VERSION ""

NS_ :

BS_:

BU_: Gateway BMS MCU VCU
VAL_TABLE_ vtbSensorReqCause 15 "SNA" 2 "by Request 2" 1 "by Request 1" 0 "normal cycle" ;
VAL_TABLE_ vtbErrorDescription 255 "ERROR" ;

BO_ 771 m_BMS_DiagRes: 2 BMS
 SG_ s_BMS_SoT_DiagRes : 8|8@1+ (1,0) [0|255] ""  Gateway
 SG_ s_BMS_SoC_DiagRes : 0|8@1+ (1,0) [0|255] ""  Gateway

BO_ 770 m_VCU_DiagRes: 2 VCU
 SG_ s_VCU_Accel_DiagRes : 0|8@1+ (1,0) [0|255] ""  Gateway
 SG_ s_VCU_Transmisson_DiagRes : 8|8@1+ (1,0) [0|255] ""  Gateway

BO_ 769 m_BMS_DiagReq: 1 Gateway
 SG_ s_BMS_DiagReq : 0|1@1+ (1,0) [0|1] ""  BMS

BO_ 768 m_VCU_DiagReq: 1 Gateway
 SG_ s_VCU_DiagReq : 0|1@1+ (1,0) [0|1] ""  VCU

BO_ 514 m_EPIT_BatteryInfo: 4 Gateway
 SG_ s_ChargeValue : 0|16@1+ (1,0) [0|65535] ""  BMS

BO_ 513 m_Vehicle_BatteryInfo: 1 BMS
 SG_ s_SoC : 0|7@1+ (1,0) [0|127] ""  Gateway

BO_ 512 m_Vehicle_DoneConnect: 1 Gateway
 SG_ s_Vehicle_Connet : 0|1@1+ (1,0) [0|1] ""  BMS

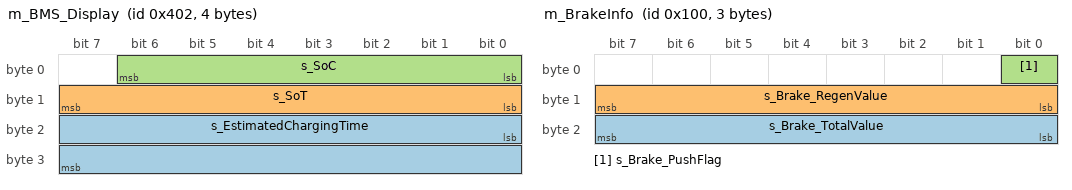
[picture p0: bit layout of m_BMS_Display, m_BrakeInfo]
BO_ 1026 m_BMS_Display: 4 BMS
 SG_ s_EstimatedChargingTime : 16|16@1+ (1,0) [0|65535] "" Vector__XXX
 SG_ s_SoT : 8|8@1- (1,0) [-128|127] ""  Gateway
 SG_ s_SoC : 0|7@1+ (1,0) [0|127] ""  Gateway

BO_ 1025 m_VCU_Display: 2 VCU
 SG_ s_GearMode : 8|2@1+ (1,0) [0|3] ""  Gateway
 SG_ s_Velocity : 0|8@1+ (1,0) [0|255] ""  Gateway

BO_ 1024 m_BatteryInfo: 2 BMS
 SG_ s_SoT : 8|8@1- (1,0) [-128|127] ""  Gateway,VCU
 SG_ s_SoC : 0|7@1+ (1,0) [0|100] ""  Gateway,VCU

BO_ 258 m_CurTorque: 1 MCU
 SG_ s_CurTorque : 0|8@1+ (1,0) [0|255] ""  VCU

BO_ 259 m_RefTorque: 1 VCU
 SG_ s_RefTorque : 0|8@1+ (1,0) [0|255] ""  MCU

BO_ 256 m_BrakeInfo: 3 Gateway
 SG_ s_Brake_TotalValue : 16|8@1+ (1,0) [0|255] ""  VCU
 SG_ s_Brake_RegenValue : 8|8@1+ (1,0) [0|255] ""  VCU
 SG_ s_Brake_PushFlag : 0|1@1+ (1,0) [0|1] ""  VCU

BO_ 257 m_KeyMode: 1 Gateway
 SG_ s_KeyMode : 0|2@1+ (1,0) [0|2] ""  VCU

BA_DEF_  "Manufacturer" STRING ;
BA_DEF_ BU_  "NodeLayerModules" STRING ;
BA_DEF_  "BusType" STRING ;
BA_DEF_ SG_  "GenSigStartValue" FLOAT 0 1215752192;
BA_DEF_ SG_  "GenSigSendType" ENUM  "Cyclic","OnWrite","OnWriteWithRepetition","OnChange","OnChangeWithRepetition","IfActive","IfActiveWithRepetition","NoSigSendType","NotUsed","NotUsed","NotUsed","NotUsed","NotUsed";
BA_DEF_ BO_  "GenMsgSendType" ENUM  "Cyclic","NotUsed","NotUsed","NotUsed","NotUsed","Cyclic","NotUsed","IfActive","NoMsgSendType","NotUsed","vector_leerstring";
BA_DEF_ BO_  "GenMsgCycleTime" INT 0 50000;
BA_DEF_ BO_  "GenMsgCycleTimeFast" INT 0 50000;
BA_DEF_ BO_  "GenMsgILSupport" ENUM  "No","Yes";
BA_DEF_DEF_  "Manufacturer" "Vector";
BA_DEF_DEF_  "NodeLayerModules" "CANoeILNLVector.dll";
BA_DEF_DEF_  "BusType" "CAN";
BA_DEF_DEF_  "GenSigStartValue" 0;
BA_DEF_DEF_  "GenSigSendType" "Cyclic";
BA_DEF_DEF_  "GenMsgSendType" "NoMsgSendType";
BA_DEF_DEF_  "GenMsgCycleTime" 200;
BA_DEF_DEF_  "GenMsgCycleTimeFast" 20;
BA_DEF_DEF_  "GenMsgILSupport" "Yes";
BA_ "GenMsgSendType" BO_ 771 7;
BA_ "GenMsgSendType" BO_ 770 7;
BA_ "GenMsgSendType" BO_ 769 7;
BA_ "GenMsgSendType" BO_ 768 7;
BA_ "GenMsgSendType" BO_ 514 0;
BA_ "GenMsgCycleTime" BO_ 514 1000;
BA_ "GenMsgSendType" BO_ 513 0;
BA_ "GenMsgCycleTime" BO_ 513 1000;
BA_ "GenMsgSendType" BO_ 512 7;
BA_ "GenMsgSendType" BO_ 1026 0;
BA_ "GenMsgCycleTime" BO_ 1026 1000;
BA_ "GenMsgSendType" BO_ 1025 0;
BA_ "GenMsgCycleTime" BO_ 1025 100;
BA_ "GenMsgSendType" BO_ 1024 0;
BA_ "GenMsgCycleTime" BO_ 1024 100;
BA_ "GenMsgSendType" BO_ 258 0;
BA_ "GenMsgCycleTime" BO_ 258 10;
BA_ "GenMsgSendType" BO_ 259 0;
BA_ "GenMsgCycleTime" BO_ 259 10;
BA_ "GenMsgSendType" BO_ 256 0;
BA_ "GenMsgCycleTime" BO_ 256 10;
BA_ "GenMsgSendType" BO_ 257 7;
